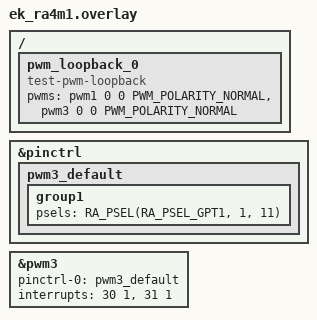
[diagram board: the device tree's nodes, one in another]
/*
 * Copyright (c) 2025 Renesas Electronics Corporation
 *
 * SPDX-License-Identifier: Apache-2.0
 */

#include <zephyr/dt-bindings/pwm/pwm.h>
#include <zephyr/dt-bindings/pwm/ra_pwm.h>

/ {
	pwm_loopback_0 {
		compatible = "test-pwm-loopback";
		/* first index must be a 32-Bit timer */
		pwms = <&pwm1 0 0 PWM_POLARITY_NORMAL>,
		       <&pwm3 0 0 PWM_POLARITY_NORMAL>;
	};
};

&pinctrl {
	pwm3_default: pwm3_default {
		group1 {
			/* GTIOC3A */
			psels = <RA_PSEL(RA_PSEL_GPT1, 1, 11)>;
		};
	};
};

&pwm3 {
	pinctrl-0 = <&pwm3_default>;
	pinctrl-names = "default";
	interrupts = <30 1>, <31 1>;
	interrupt-names = "gtioca", "overflow";
	status = "okay";
};
